# SYSCTL_1.0 register map
Vendor: Texas Instruments
Peripheral module from a debugger description file (folder mspm33c321x).
Registers are 32-bit, read-write, no defined reset value unless marked. A register's access mark holds for its fields unless they carry their own. Offsets are as the file gives them; lines under a group give offsets from that group; [hi:lo] are bit positions; {n}, {i} and the like mark numbered series; 'fields as' and 'values as' point back to an identical list; <NAME> marks a mode.

## SYSCTL (part 1 of 2)
0x800 SYSCTL_MGMT_M33ADC12B4MSPS0_PWREN — IP Enable Register
  [0] ENABLE — IP Enable
    0=Disable; 1=Enable
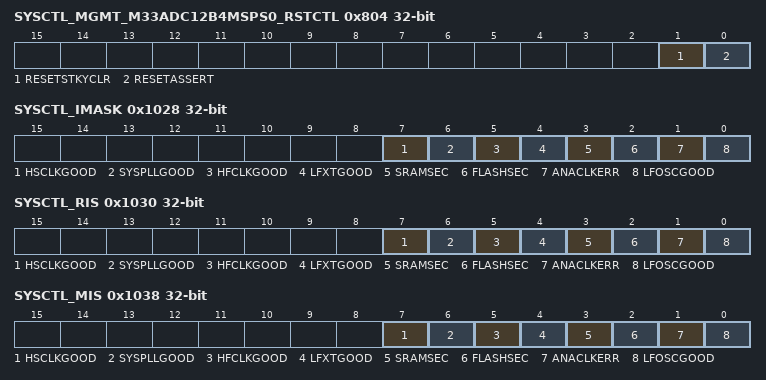
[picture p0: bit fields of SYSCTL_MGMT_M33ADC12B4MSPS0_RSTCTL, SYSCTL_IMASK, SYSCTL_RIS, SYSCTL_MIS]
0x804 SYSCTL_MGMT_M33ADC12B4MSPS0_RSTCTL — Power Control Register - Write Only Register, Always Read as 0
  [1] RESETSTKYCLR — Clear the RESET STICKY Bit
    1=Clear
  [0] RESETASSERT — Assert Reset to IP Domain.
    1=Do
0x814 SYSCTL_MGMT_M33ADC12B4MSPS0_STAT ro — IP State Register - Read Only
  [16] RESETSTKY — IP has been Reset
    0=clear; 1=Set
0x1020 SYSCTL_IIDX ro — SYSCTL interrupt index
  [3:0] STAT — The SYSCTL interrupt index (IIDX) register generates a value corresponding to the highest priority pending interrupt source. This value may be used as an address offset for fast, deterministic handling in the interrupt service routine. A read of the IIDX register will clear the corresponding interrupt status in the RIS and MIS registers.
    0=NO_INTR (No interrupt pending); 1=LFOSCGOOD (LFOSCGOOD interrupt pending); 2=ANACLKERR; 3=FLASHSEC; 4=SRAMSEC; 5=LFXTGOOD; 6=HFCLKGOOD; 7=SYSPLLGOOD; 8=HSCLKGOOD
0x1028 SYSCTL_IMASK — SYSCTL interrupt mask
  [7] HSCLKGOOD
    0=DISABLE; 1=ENABLE
  [6] SYSPLLGOOD
    0=DISABLE; 1=ENABLE
  [5] HFCLKGOOD
    0=DISABLE; 1=ENABLE
  [4] LFXTGOOD
    0=DISABLE; 1=ENABLE
  [3] SRAMSEC — SRAM Single Error Correct
    0=DISABLE; 1=ENABLE
  [2] FLASHSEC — Flash Single Error Correct
    0=DISABLE; 1=ENABLE
  [1] ANACLKERR — Analog Clocking Consistency Error
    0=DISABLE; 1=ENABLE
  [0] LFOSCGOOD — Enable or disable the LFOSCGOOD interrupt. LFOSCGOOD indicates that the LFOSC has started successfully.
    0=DISABLE (Interrupt disabled); 1=ENABLE (Interrupt enabled)
0x1030 SYSCTL_RIS ro — SYSCTL raw interrupt status
  [7] HSCLKGOOD
    0=FALSE; 1=TRUE
  [6] SYSPLLGOOD
    0=FALSE; 1=TRUE
  [5] HFCLKGOOD
    0=FALSE; 1=TRUE
  [4] LFXTGOOD
    0=FALSE; 1=TRUE
  [3] SRAMSEC — SRAM Single Error Correct
    0=FALSE; 1=TRUE
  [2] FLASHSEC — Flash Single Error Correct
    0=FALSE; 1=TRUE
  [1] ANACLKERR — Analog Clocking Consistency Error
    0=FALSE; 1=TRUE
  [0] LFOSCGOOD — Raw status of the LFOSCGOOD interrupt.
    0=FALSE (No interrupt pending); 1=TRUE (Interrupt pending)
0x1038 SYSCTL_MIS ro — SYSCTL masked interrupt status
  [7] HSCLKGOOD
    0=FALSE; 1=TRUE
  [6] SYSPLLGOOD
    0=FALSE; 1=TRUE
  [5] HFCLKGOOD
    0=FALSE; 1=TRUE
  [4] LFXTGOOD
    0=FALSE; 1=TRUE
  [3] SRAMSEC — SRAM Single Error Correct
    0=FALSE; 1=TRUE
  [2] FLASHSEC — Flash Single Error Correct
    0=FALSE; 1=TRUE
  [1] ANACLKERR — Analog Clocking Consistency Error
    0=FALSE; 1=TRUE
  [0] LFOSCGOOD — Masked status of the LFOSCGOOD interrupt.
    0=FALSE (No interrupt pending); 1=TRUE (Interrupt pending)
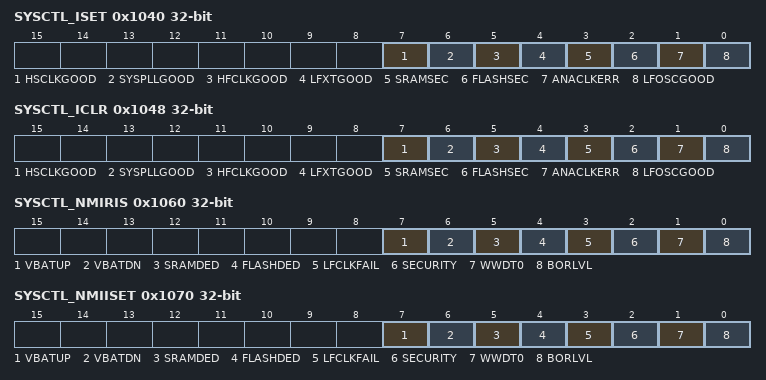
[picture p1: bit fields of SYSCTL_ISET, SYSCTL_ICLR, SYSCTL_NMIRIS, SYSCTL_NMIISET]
0x1040 SYSCTL_ISET — SYSCTL interrupt set
  [7] HSCLKGOOD
    0=NO_EFFECT; 1=SET
  [6] SYSPLLGOOD
    0=NO_EFFECT; 1=SET
  [5] HFCLKGOOD
    0=NO_EFFECT; 1=SET
  [4] LFXTGOOD
    0=NO_EFFECT; 1=SET
  [3] SRAMSEC — SRAM Single Error Correct
    0=NO_EFFECT; 1=SET
  [2] FLASHSEC — Flash Single Error Correct
    0=NO_EFFECT; 1=SET
  [1] ANACLKERR — Analog Clocking Consistency Error
    0=NO_EFFECT; 1=SET
  [0] LFOSCGOOD — Set the LFOSCGOOD interrupt.
    0=NO_EFFECT (Writing 0h hs no effect); 1=SET (Set interrupt)
0x1048 SYSCTL_ICLR — SYSCTL interrupt clear
  [7] HSCLKGOOD
    0=NO_EFFECT; 1=CLR
  [6] SYSPLLGOOD
    0=NO_EFFECT; 1=CLR
  [5] HFCLKGOOD
    0=NO_EFFECT; 1=CLR
  [4] LFXTGOOD
    0=NO_EFFECT; 1=CLR
  [3] SRAMSEC — SRAM Single Error Correct
    0=NO_EFFECT; 1=CLR
  [2] FLASHSEC — Flash Single Error Correct
    0=NO_EFFECT; 1=CLR
  [1] ANACLKERR — Analog Clocking Consistency Error
    0=NO_EFFECT; 1=CLR
  [0] LFOSCGOOD — Clear the LFOSCGOOD interrupt.
    0=NO_EFFECT (Writing 0h has no effect); 1=CLR (Clear interrupt)
0x1050 SYSCTL_NMIIIDX ro — NMI interrupt index
  [3:0] STAT — The NMI interrupt index (NMIIIDX) register generates a value corresponding to the highest priority pending NMI source. This value may be used as an address offset for fast, deterministic handling in the NMI service routine. A read of the NMIIIDX register will clear the corresponding interrupt status in the NMIRIS register.
    0=NO_INTR (No NMI pending); 1=BORLVL (BOR Threshold NMI pending); 2=WWDT0; 3=SECURITY; 4=LFCLKFAIL; 5=FLASHDED; 6=SRAMDED; 7=VBATDN; 8=VBATUP
0x1060 SYSCTL_NMIRIS ro — NMI raw interrupt status
  [7] VBATUP — VBAT Power On
    0=FALSE; 1=TRUE
  [6] VBATDN — VBAT Power Off
    0=FALSE; 1=TRUE
  [5] SRAMDED — SRAM Double Error Detect
    0=FALSE; 1=TRUE
  [4] FLASHDED — Flash Double Error Detect
    0=FALSE; 1=TRUE
  [3] LFCLKFAIL — LFXT-EXLF Monitor Fail
    0=FALSE; 1=TRUE
  [2] SECURITY — Security Fault
    0=FALSE; 1=TRUE
  [1] WWDT0 — Watch Dog 0 Fault
    0=FALSE; 1=TRUE
  [0] BORLVL — Raw status of the BORLVL NMI
    0=FALSE (No interrupt pending); 1=TRUE (Interrupt pending)
0x1070 SYSCTL_NMIISET — NMI interrupt set
  [7] VBATUP — VBAT Power On
    0=NO_EFFECT; 1=SET
  [6] VBATDN — VBAT Power Off
    0=NO_EFFECT; 1=SET
  [5] SRAMDED — SRAM Double Error Detect
    0=NO_EFFECT; 1=SET
  [4] FLASHDED — Flash Double Error Detect
    0=NO_EFFECT; 1=SET
  [3] LFCLKFAIL — LFXT-EXLF Monitor Fail
    0=NO_EFFECT; 1=SET
  [2] SECURITY — Security Fault
    0=NO_EFFECT; 1=SET
  [1] WWDT0 — Watch Dog 0 Fault
    0=NO_EFFECT; 1=SET
  [0] BORLVL — Set the BORLVL NMI
    0=NO_EFFECT (Writing 0h hs no effect); 1=SET (Set interrupt)
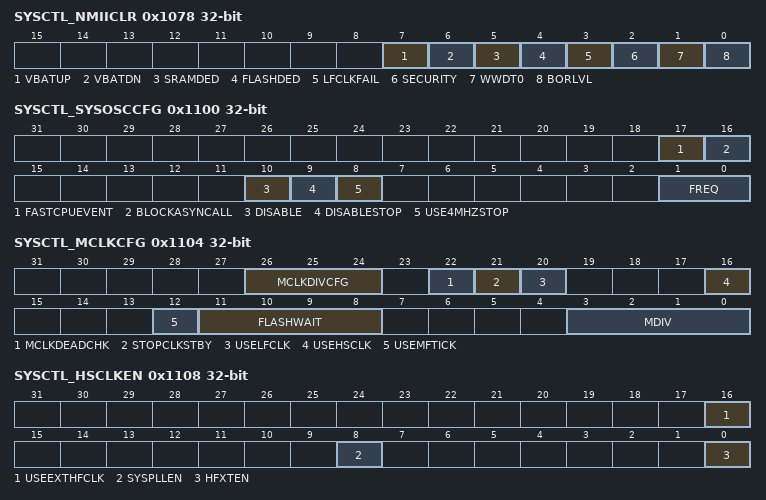
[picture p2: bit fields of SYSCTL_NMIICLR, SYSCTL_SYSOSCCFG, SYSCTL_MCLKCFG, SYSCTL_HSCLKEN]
0x1078 SYSCTL_NMIICLR — NMI interrupt clear
  [7] VBATUP — VBAT Power On
    0=NO_EFFECT; 1=CLR
  [6] VBATDN — VBAT Power Off
    0=NO_EFFECT; 1=CLR
  [5] SRAMDED — SRAM Double Error Detect
    0=NO_EFFECT; 1=CLR
  [4] FLASHDED — Flash Double Error Detect
    0=NO_EFFECT; 1=CLR
  [3] LFCLKFAIL — LFXT-EXLF Monitor Fail
    0=NO_EFFECT; 1=CLR
  [2] SECURITY — Security Fault
    0=NO_EFFECT; 1=CLR
  [1] WWDT0 — Watch Dog 0 Fault
    0=NO_EFFECT; 1=CLR
  [0] BORLVL — Clr the BORLVL NMI
    0=NO_EFFECT (Writing 0h hs no effect); 1=CLR (Clear interrupt)
0x1100 SYSCTL_SYSOSCCFG access per field — SYSOSC configuration
  [17] FASTCPUEVENT rw — if disabled CPU will not wakeup and continue in STANDBY
    0=DISABLE (An interrupt to the CPU will not assert a fast clock request); 1=ENABLE (An interrupt to the CPU will assert a fast clock request)
  [16] BLOCKASYNCALL rw — BLOCKASYNCALL may be used to mask block all asynchronous fast clock requests, preventing hardware from dynamically changing the active clock configuration when operating in a given mode.
    0=DISABLE (Asynchronous fast clock requests are controlled by the requesting peripheral); 1=ENABLE (All asynchronous fast clock requests are blocked)
  [10] DISABLE ro — DISABLE sets the SYSOSC enable/disable policy. SYSOSC may be powered off in RUN, SLEEP, and STOP modes to reduce power consumption. When SYSOSC is disabled, MCLK and ULPCLK are sourced from LFCLK.
    0=DISABLE (Do not disable SYSOSC); 1=ENABLE (Disable SYSOSC immediately and source MCLK and ULPCLK from LFCLK)
  [9] DISABLESTOP ro — DISABLESTOP sets the SYSOSC stop mode enable/disable policy. When operating in STOP mode, the SYSOSC may be automatically disabled. When set, ULPCLK will run from LFCLK in STOP mode and SYSOSC will be disabled to reduce power consumption.
    0=DISABLE (Do not disable SYSOSC in STOP mode); 1=ENABLE (Disable SYSOSC in STOP mode and source ULPCLK from LFCLK)
  [8] USE4MHZSTOP ro — USE4MHZSTOP sets the SYSOSC stop mode frequency policy. When entering STOP mode, the SYSOSC frequency may be automatically switched to 4MHz to reduce SYSOSC power consumption.
    0=DISABLE (Do not gear shift the SYSOSC to 4MHz in STOP mode); 1=ENABLE (Gear shift SYSOSC to 4MHz in STOP mode)
  [1:0] FREQ rw — Target operating frequency for the system oscillator (SYSOSC)
    0=SYSOSCBASE (Base frequency (32MHz)); 1=SYSOSC4M (Low frequency (4MHz))
0x1104 SYSCTL_MCLKCFG access per field — Main clock (MCLK) configuration
  [26:24] MCLKDIVCFG rw — MCLK Divider Configuration bits [1:0] are defined as MCLK4 is Bypass, MCLK2 is Bypass
  [22] MCLKDEADCHK rw — MCLKDEADCHK enables or disables the continuous MCLK dead check monitor. LFCLK must be running before MCLKDEADCHK is enabled.
    0=DISABLE (The MCLK dead check monitor is disabled); 1=ENABLE (The MCLK dead check monitor is enabled)
  [21] STOPCLKSTBY rw — STOPCLKSTBY sets the STANDBY mode policy (STANDBY0 or STANDBY1). When set, ULPCLK and LFCLK are disabled to all peripherals in STANDBY mode, with the exception of TIMG0 and TIMG1 which continue to run. Wake-up is only possible via an asynchronous fast clock request.
    0=DISABLE (ULPCLK/LFCLK runs to all PD0 peripherals in STANDBY mode); 1=ENABLE (ULPCLK/LFCLK is disabled to all peripherals in STANDBY mode except TIMG0 and TIMG1)
  [20] USELFCLK ro — LFCLK is not an MCLK sourcei in PD1, tied 0.
    0=DISABLE (MCLK will not use the low frequency clock (LFCLK)); 1=ENABLE (MCLK will use the low frequency clock (LFCLK))
  [16] USEHSCLK rw — USEHSCLK, together with USELFCLK, sets the MCLK source policy. Set USEHSCLK to use HSCLK (HFCLK or SYSPLL) as the MCLK source in RUN and SLEEP modes.
    0=DISABLE (MCLK will not use the high speed clock (HSCLK)); 1=ENABLE (MCLK will use the high speed clock (HSCLK) in RUN and SLEEP mode)
  [12] USEMFTICK rw — USEMFTICK specifies whether the 4MHz constant-rate clock (MFCLK) to peripherals is enabled or disabled. When enabled, MDIV must be disabled (set to 0h=/1).
    0=DISABLE (The 4MHz rate MFCLK to peripherals is enabled); 1=ENABLE (The 4MHz rate MFCLK to peripherals is enabled.)
  [11:8] FLASHWAIT rw — Not used in design
    0=WAIT0 (No flash wait states are applied); 1=WAIT1 (One flash wait state is applied); 2=WAIT2 (2 flash wait states are applied)
  [3:0] MDIV ro — MDIV tied to 0
0x1108 SYSCTL_HSCLKEN — High-speed clock (HSCLK) source enable/disable
  [16] USEEXTHFCLK — USEEXTHFCLK selects the HFCLK_IN digital clock input to be the source for HFCLK. When disabled, HFXT is the HFCLK source and HFXTEN may be set. Do not set HFXTEN and USEEXTHFCLK simultaneously.
    0=DISABLE (Use HFXT as the HFCLK source); 1=ENABLE (Use the HFCLK_IN digital clock input as the HFCLK source)
  [8] SYSPLLEN — SYSPLLEN enables or disables the system phase-lock loop (SYSPLL).
    0=DISABLE (Disable the SYSPLL); 1=ENABLE (Enable the SYSPLL)
  [0] HFXTEN — HFXTEN enables or disables the high frequency crystal oscillator (HFXT).
    0=DISABLE (Disable the HFXT); 1=ENABLE (Enable the HFXT)
0x110C SYSCTL_HSCLKCFG — High-speed clock (HSCLK) source selection
  [0] HSCLKSEL — HSCLKSEL selects the HSCLK source (SYSPLL or HFCLK).
    0=SYSPLL (HSCLK is sourced from the SYSPLL); 1=HFCLKCLK (HSCLK is sourced from the HFCLK)
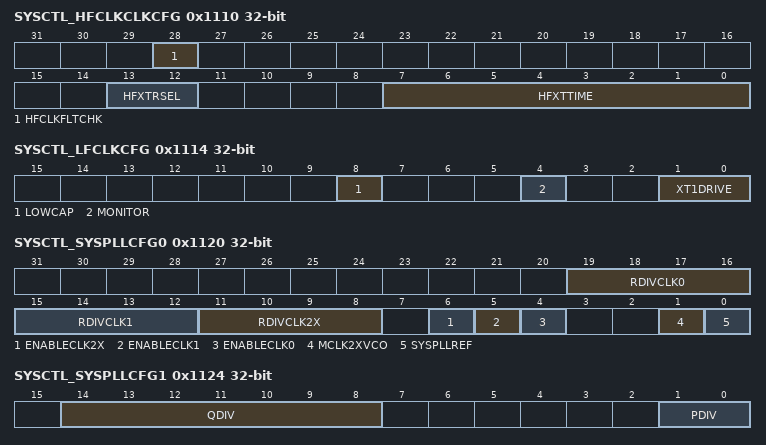
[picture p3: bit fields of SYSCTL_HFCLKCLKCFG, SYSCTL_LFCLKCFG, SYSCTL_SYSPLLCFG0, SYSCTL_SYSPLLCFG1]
0x1110 SYSCTL_HFCLKCLKCFG — High-frequency clock (HFCLK) configuration
  [28] HFCLKFLTCHK — HFCLKFLTCHK enables or disables the HFCLK startup monitor.
    0=DISABLE (HFCLK startup is not checked); 1=ENABLE (HFCLK startup is checked)
  [13:12] HFXTRSEL — HFXT Range Select
    0=RANGE4TO8 (4MHz <= HFXT frequency <= 8MHz); 1=RANGE8TO16 (8MHz < HFXT frequency <= 16MHz); 2=RANGE16TO32 (16MHz < HFXT frequency <= 32MHz); 3=RANGE32TO48 (32MHz < HFXT frequency <= 48MHz)
  [7:0] HFXTTIME — HFXTTIME specifies the HFXT startup time in 64us resolution. If the HFCLK startup monitor is enabled (HFCLKFLTCHK), HFXT will be checked after this time expires.
    0=MINSTARTTIME (Minimum startup time (approximatly zero)); 255=MAXSTARTTIME (Maximum startup time (approximatly 16.32ms))
0x1114 SYSCTL_LFCLKCFG — Low frequency crystal oscillator (LFXT) configuration
  [8] LOWCAP — LOWCAP controls the low-power LFXT mode. When the LFXT load capacitance is less than 3pf, LOWCAP may be set for reduced power consumption.
    0=DISABLE (LFXT low capacitance mode is disabled); 1=ENABLE (LFXT low capacitance mode is enabled)
  [4] MONITOR — MONITOR enables or disables the LFCLK monitor, which continuously checks LFXT or LFCLK_IN for a clock stuck fault.
    0=DISABLE (Clock monitor is disabled); 1=ENABLE (Clock monitor is enabled)
  [1:0] XT1DRIVE — XT1DRIVE selects the low frequency crystal oscillator (LFXT) drive strength.
    0=LOWESTDRV (Lowest drive and current); 1=LOWERDRV (Lower drive and current); 2=HIGHERDRV (Higher drive and current); 3=HIGHESTDRV (Highest drive and current)
0x1120 SYSCTL_SYSPLLCFG0 — SYSPLL reference and output configuration
  [19:16] RDIVCLK0 — RDIVCLK0 sets the final divider for the SYSPLLCLK0 output.
    0=CLK0DIV2 (SYSPLLCLK0 is divided by 2); 1=CLK0DIV4 (SYSPLLCLK0 is divided by 4); 2=CLK0DIV6 (SYSPLLCLK0 is divided by 6); 3=CLK0DIV8 (SYSPLLCLK0 is divided by 8); 4=CLK0DIV10 (SYSPLLCLK0 is divided by 10); 5=CLK0DIV12 (SYSPLLCLK0 is divided by 12); 6=CLK0DIV14 (SYSPLLCLK0 is divided by 14); 7=CLK0DIV16 (SYSPLLCLK0 is divided by 16); 8=CLK0DIV18 (SYSPLLCLK0 is divided by 18); 9=CLK0DIV20 (SYSPLLCLK0 is divided by 20); 10=CLK0DIV22 (SYSPLLCLK0 is divided by 22); 11=CLK0DIV24 (SYSPLLCLK0 is divided by 24); 12=CLK0DIV26 (SYSPLLCLK0 is divided by 26); 13=CLK0DIV28 (SYSPLLCLK0 is divided by 28); 14=CLK0DIV30 (SYSPLLCLK0 is divided by 30); 15=CLK0DIV32 (SYSPLLCLK0 is divided by 32)
  [15:12] RDIVCLK1 — RDIVCLK1 sets the final divider for the SYSPLLCLK1 output.
    0=CLK1DIV2 (SYSPLLCLK1 is divided by 2); 1=CLK1DIV4 (SYSPLLCLK1 is divided by 4); 2=CLK1DIV6 (SYSPLLCLK1 is divided by 6); 3=CLK1DIV8 (SYSPLLCLK1 is divided by 8); 4=CLK1DIV10 (SYSPLLCLK1 is divided by 10); 5=CLK1DIV12 (SYSPLLCLK1 is divided by 12); 6=CLK1DIV14 (SYSPLLCLK1 is divided by 14); 7=CLK1DIV16 (SYSPLLCLK1 is divided by 16); 8=CLK1DIV18 (SYSPLLCLK1 is divided by 18); 9=CLK1DIV20 (SYSPLLCLK1 is divided by 20); 10=CLK1DIV22 (SYSPLLCLK1 is divided by 22); 11=CLK1DIV24 (SYSPLLCLK1 is divided by 24); 12=CLK1DIV26 (SYSPLLCLK1 is divided by 26); 13=CLK1DIV28 (SYSPLLCLK1 is divided by 28); 14=CLK1DIV30 (SYSPLLCLK1 is divided by 30); 15=CLK1DIV32 (SYSPLLCLK1 is divided by 32)
  [11:8] RDIVCLK2X — RDIVCLK2X sets the final divider for the SYSPLLCLK2X output.
    {v}=CLK2XDIV{v+1} (SYSPLLCLK1 is divided by {v+1}) (v=0..15)
  [6] ENABLECLK2X — ENABLECLK2X enables or disables the SYSPLLCLK2X output.
    0=DISABLE (SYSPLLCLK2X is disabled); 1=ENABLE (SYSPLLCLK2X is enabled)
  [5] ENABLECLK1 — ENABLECLK1 enables or disables the SYSPLLCLK1 output.
    0=DISABLE (SYSPLLCLK1 is disabled); 1=ENABLE (SYSPLLCLK1 is enabled)
  [4] ENABLECLK0 — ENABLECLK0 enables or disables the SYSPLLCLK0 output.
    0=DISABLE (SYSPLLCLK0 is disabled); 1=ENABLE (SYSPLLCLK0 is enabled)
  [1] MCLK2XVCO — MCLK2XVCO selects the SYSPLL output which is sent to the HSCLK mux for use by MCLK.
    0=DISABLE (The SYSPLLCLK0 output is sent to the HSCLK mux); 1=ENABLE (The SYSPLLCLK2X output is sent to the HSCLK mux)
  [0] SYSPLLREF — SYSPLLREF selects the system PLL (SYSPLL) reference clock source.
    0=SYSOSC (SYSPLL reference is SYSOSC); 1=HFCLK (SYSPLL reference is HFCLK)
0x1124 SYSCTL_SYSPLLCFG1 — SYSPLL reference and feedback divider
  [14:8] QDIV — QDIV selects the SYSPLL feedback path divider.
    0=INVALID (Divide-by-one is not a valid QDIV option); 1=QDIVMIN (Feedback path is divided by 2); 126=QDIVMAX (Feedback path is divided by 127 (0x7E))
  [1:0] PDIV — PDIV selects the SYSPLL reference clock prescale divider.
    0=REFDIV1 (SYSPLLREF is not divided); 1=REFDIV2 (SYSPLLREF is divided by 2); 2=REFDIV4 (SYSPLLREF is divided by 4); 3=REFDIV8 (SYSPLLREF is divided by 8)
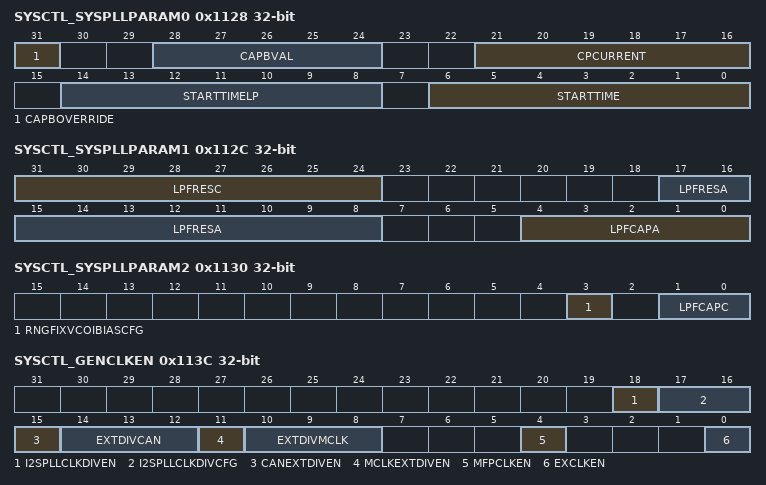
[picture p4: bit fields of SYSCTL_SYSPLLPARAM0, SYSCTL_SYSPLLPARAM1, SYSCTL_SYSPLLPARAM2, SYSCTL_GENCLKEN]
0x1128 SYSCTL_SYSPLLPARAM0 — SYSPLL PARAM0 (load from FACTORY region)
  [31] CAPBOVERRIDE — CAPBOVERRIDE controls the override for Cap B
    0=DISABLE (Cap B override disabled); 1=ENABLE (Cap B override enabled)
  [28:24] CAPBVAL — Override value for Cap B
  [21:16] CPCURRENT — Charge pump current
  [14:8] STARTTIMELP — Startup time from low power mode exit to locked clock, in 1us resolution
  [6:0] STARTTIME — Startup time from enable to locked clock, in 1us resolution
0x112C SYSCTL_SYSPLLPARAM1 — SYSPLL PARAM1 (load from FACTORY region)
  [31:24] LPFRESC — Loop filter Res C
  [17:8] LPFRESA — Loop filter Res A
  [4:0] LPFCAPA — Loop filter Cap A
0x1130 SYSCTL_SYSPLLPARAM2 — SYSPLL PARAM2 (load from FACTORY region)
  [3] RNGFIXVCOIBIASCFG — 0 value for Temperature Compensation R addition
  [1:0] LPFCAPC — Loop filter Cap C
0x1134 SYSCTL_SYSPLLLDOCTL — SYSPLL LDO CTL (load from FACTORY region)
  [15:0] LDOCTLLOWV — LDO Configurability
0x1138 SYSCTL_SYSPLLLDOPROG — SYSPLL LDO VOUT PROG (load from FACTORY region)
  [2:0] LDOVOUTPROGLOWV — HPLL LDO Vout Prog
0x113C SYSCTL_GENCLKEN — General clock enable control
  [18] I2SPLLCLKDIVEN — I2SPLLCLKDIVEN enables or disables the divider function of the PLL Source to I2S.
    0=PASSTHRU (CLock divider is disabled (passthrough, I2SPLLCLKDIV is not applied)); 1=ENABLE (Clock divider is enabled (I2SPLLCLKDIV is applied))
  [17:16] I2SPLLCLKDIVCFG — I2SPLLCLKDIVCFG selects the divider value for the divider for the PLL Source to CAN.
    0=DIV4 (CLK_OUT source is divided by 4); 1=DIV8 (CLK_OUT source is divided by 8); 2=DIV12 (CLK_OUT source is divided by 12); 3=DIV16 (CLK_OUT source is divided by 16)
  [15] CANEXTDIVEN — CANEXTDIVEN enables or disables the divider function of the PLL Source to CAN.
    0=PASSTHRU (CLock divider is disabled (passthrough, EXTDIVCAN is not applied)); 1=ENABLE (Clock divider is enabled (EXTDIVCAN is applied))
  [14:12] EXTDIVCAN — EXTDIVCAN selects the divider value for the divider for the PLL Source to CAN.
    0=DIV2 (CLK_OUT source is divided by 2); 1=DIV4 (CLK_OUT source is divided by 4); 2=DIV6 (CLK_OUT source is divided by 6); 3=DIV8 (CLK_OUT source is divided by 8); 4=DIV10 (CLK_OUT source is divided by 10); 5=DIV12 (CLK_OUT source is divided by 12); 6=DIV14 (CLK_OUT source is divided by 14); 7=DIV16 (CLK_OUT source is divided by 16)
  [11] MCLKEXTDIVEN — MCLKEXTDIVEN enables or disables the divider function of the PLL Source to MCLK.
    0=PASSTHRU (CLock divider is disabled (passthrough, EXTDIVMCLK is not applied)); 1=ENABLE (Clock divider is enabled (EXTDIVMCLK is applied))
  [10:8] EXTDIVMCLK — EXTDIVMCLK selects the divider value for the divider for the PLL Source MCLK.
    values as EXTDIVCAN
  [4] MFPCLKEN — MFPCLKEN tied 0, since DAC is not present
    0=DISABLE (MFPCLK is disabled); 1=ENABLE (MFPCLK is enabled)
  [0] EXCLKEN — EXCLKEN enables the CLK_OUT external clock output block.
    0=DISABLE (CLK_OUT block is disabled); 1=ENABLE (CLK_OUT block is enabled)
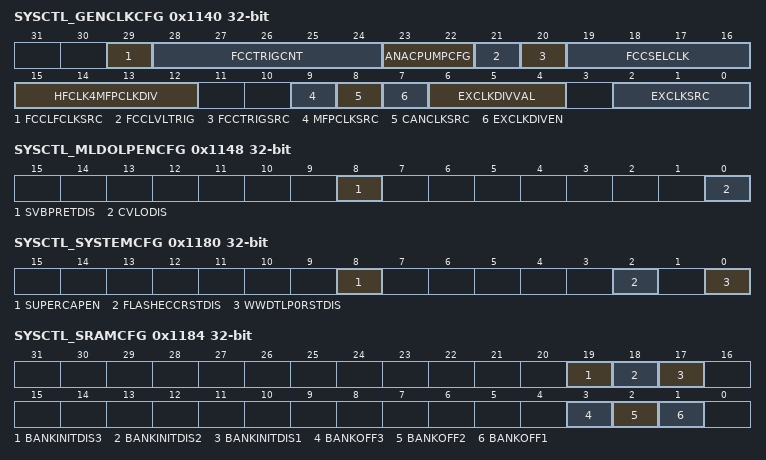
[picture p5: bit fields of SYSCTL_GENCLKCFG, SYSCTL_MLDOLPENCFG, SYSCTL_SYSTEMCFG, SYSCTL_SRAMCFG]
0x1140 SYSCTL_GENCLKCFG — General clock configuration
  [29] FCCLFCLKSRC — FCCLFCLKSRC selects between SYSTEM LFCLK and EXTERNAL SOURCED LFCLK.
  [28:24] FCCTRIGCNT — FCCTRIGCNT specifies the number of trigger clock periods in the trigger window. FCCTRIGCNT=0h (one trigger clock period) up to 1Fh (32 trigger clock periods) may be specified.
  [23:22] ANACPUMPCFG — ANACPUMPCFG selects the analog mux charge pump (VBOOST) enable method.
    0=ONDEMAND (VBOOST is enabled on request from a COMP, GPAMP, or OPA); 1=ONACTIVE (VBOOST is enabled when the device is in RUN or SLEEP mode, or when a COMP/GPAMP/OPA is enabled); 2=ONALWAYS (VBOOST is always enabled)
  [21] FCCLVLTRIG — FCCLVLTRIG selects the frequency clock counter (FCC) trigger mode.
    0=RISE2RISE (Rising edge to rising edge triggered); 1=LEVEL (Level triggered)
  [20] FCCTRIGSRC — FCCTRIGSRC selects the frequency clock counter (FCC) trigger source.
    0=EXTPIN (FCC trigger is the external pin); 1=LFCLK (FCC trigger is the LFCLK)
  [19:16] FCCSELCLK — FCCSELCLK selectes the frequency clock counter (FCC) clock source.
    0=MCLK/4 (FCC clock is MCLK/4); 1=SYSOSC (FCC clock is SYSOSC); 2=HFCLK (FCC clock is HFCLK); 3=EXTCLK (FCC clock is the CLK_OUT selection); 4=SYSPLLCLK0 (FCC clock is SYSPLLCLK0); 5=SYSPLLCLK1 (FCC clock is SYSPLLCLK1); 6=SYSPLLCLK2X (FCC clock is SYSPLLCLK2X); 7=FCCIN (FCC clock is the FCCIN external input)
  [15:12] HFCLK4MFPCLKDIV — HFCLK4MFPCLKDIV selects the divider applied to HFCLK when HFCLK is used as the MFPCLK source. Integer dividers from /1 to /16 may be selected.
    0=DIV1 (HFCLK is not divided before being used for MFPCLK); {v}=DIV{v+1} (HFCLK is divided by {v+1} before being used for MFPCLK) (v=1..15)
  [9] MFPCLKSRC — Not used in design
    0=SYSOSC (MFPCLK is sourced from SYSOSC); 1=HFCLK (MFPCLK is sourced from HFCLK)
  [8] CANCLKSRC — CANCLKSRC selects the CANCLK source.
    0=HFCLK (CANCLK source is HFCLK); 1=SYSPLLOUT1 (CANCLK source is SYSPLLCLK1)
  [7] EXCLKDIVEN — EXCLKDIVEN enables or disables the divider function of the CLK_OUT external clock output block.
    0=PASSTHRU (CLock divider is disabled (passthrough, EXCLKDIVVAL is not applied)); 1=ENABLE (Clock divider is enabled (EXCLKDIVVAL is applied))
  [6:4] EXCLKDIVVAL — EXCLKDIVVAL selects the divider value for the divider in the CLK_OUT external clock output block.
    values as SYSCTL_GENCLKEN.EXTDIVCAN
  [2:0] EXCLKSRC — EXCLKSRC selects the source for the CLK_OUT external clock output block. ULPCLK and MFPCLK require the CLK_OUT divider (EXCLKDIVEN) to be enabled
    0=SYSOSC (CLK_OUT is SYSOSC); 1=ULPCLK (CLK_OUT is ULPCLK (EXCLKDIVEN must be enabled)); 2=LFCLK (CLK_OUT is LFCLK); 3=MFPCLK (CLK_OUT is MFPCLK (EXCLKDIVEN must be enabled)); 4=HFCLK (CLK_OUT is HFCLK); 5=SYSPLLOUT1 (CLK_OUT is SYSPLLCLK1 (SYSPLLCLK1 must be <=48MHz))
0x1144 SYSCTL_PMODECFG — Power mode configuration
  [1:0] DSLEEP — DSLEEP selects the operating mode to enter upon a DEEPSLEEP request from the CPU.
    0=STOP (STOP mode is entered); 1=STANDBY (STANDBY mode is entered); 2=SHUTDOWN (SHUTDOWN mode is entered)
0x1148 SYSCTL_MLDOLPENCFG — LDO Configuration Control
  [8] SVBPRETDIS — Control to disable the disconnect of core LDO from retention for STOP and STANDBY
    0=FALSE (Disconnect the core LDO from retention domain during STOP and STANDBY); 1=TRUE (Do Not Disconnect the core LDO from retention domain during STOP and STANDBY)
  [0] CVLODIS — Control to disable lowering the core voltage for STOP and STANDBY
    0=FALSE (Lower Core Voltage for STOP and STANDBY mode); 1=TRUE (Do Not Lower Core Voltage for STOP and STANDBY mode to provide faster wakeup)
0x1150 SYSCTL_FCC ro — Frequency clock counter (FCC) count
  [21:0] DATA — Frequency clock counter (FCC) count value.
0x1154 SYSCTL_PMULDOSPARECTL — LDO Spare Control
  [3:0] sparectrl — Spare PMU LDO control for M33
0x1158 SYSCTL_SYSCTL_ECO_REG1 access not given — Sysctl ECO Reg 1
0x115C SYSCTL_SYSCTL_ECO_REG2 access not given — Sysctl ECO Reg 2
0x1178 SYSCTL_SRAMBOUNDARY — SRAM Write Boundary
  [19:5] ADDR — Not used, GSC register is used for SRAM boundary configuration
0x117C SYSCTL_SRAMBOUNDARYHIGH — SRAM Write Boundary High
  fields as SYSCTL_SRAMBOUNDARY
0x1180 SYSCTL_SYSTEMCFG — System configuration
  [8] SUPERCAPEN — SUPERCAP specifies whether the battery backup system can be powered by a SUPERCAP
    0=FALSE (SUPERCAP Function is not enabled); 1=TRUE (SUPERCAP Function is not enabled)
  [2] FLASHECCRSTDIS — FLASHECCRSTDIS specifies whether a flash ECC double error detect (DED) will trigger a SYSRST or an NMI.
    0=FALSE (Flash ECC DED will trigger a SYSRST); 1=TRUE (Flash ECC DED will trigger a NMI)
  [0] WWDTLP0RSTDIS — WWDTLP0RSTDIS specifies whether a WWDT Error Event will trigger a BOOTRST or an NMI.
    0=FALSE (WWDTLP0 Error Event will trigger a BOOTRST); 1=TRUE (WWDTLP0 Error Event will trigger an NMI)
0x1184 SYSCTL_SRAMCFG — System SRAM configuration
  [19] BANKINITDIS3 — SRAM BANK3 Initialization
    0=FALSE (SRAM BANK3 will Initialize when transitioning from OFF to ON); 1=TRUE (SRAM BANK3 will NOT Initialize when transitioning from OFF to ON)
  [18] BANKINITDIS2 — SRAM BANK2 Initialization
    0=FALSE (SRAM BANK2 will Initialize when transitioning from OFF to ON); 1=TRUE (SRAM BANK2 will NOT Initialize when transitioning from OFF to ON)
  [17] BANKINITDIS1 — SRAM BANK1 Initialization
    0=FALSE (SRAM BANK1 will Initialize when transitioning from OFF to ON); 1=TRUE (SRAM BANK1 will NOT Initialize when transitioning from OFF to ON)
  [3] BANKOFF3 — Not used
    0=FALSE (SRAM BANK3 power ON for RUN mode); 1=TRUE (SRAM BANK3 power OFF for RUN mode)
  [2] BANKOFF2 — Not used
    0=FALSE (SRAM BANK2 power ON for RUN mode); 1=TRUE (SRAM BANK2 power OFF for RUN mode)
  [1] BANKOFF1 — Not used
    0=FALSE (SRAM BANK1 power ON for RUN mode); 1=TRUE (SRAM BANK1 power OFF for RUN mode)
0x1200 SYSCTL_WRITELOCK — SYSCTL register write lockout
  [0] ACTIVE — ACTIVE controls whether critical SYSCTL registers are write protected or not.
    0=DISABLE (Allow writes to lockable registers); 1=ENABLE (Disallow writes to lockable registers)
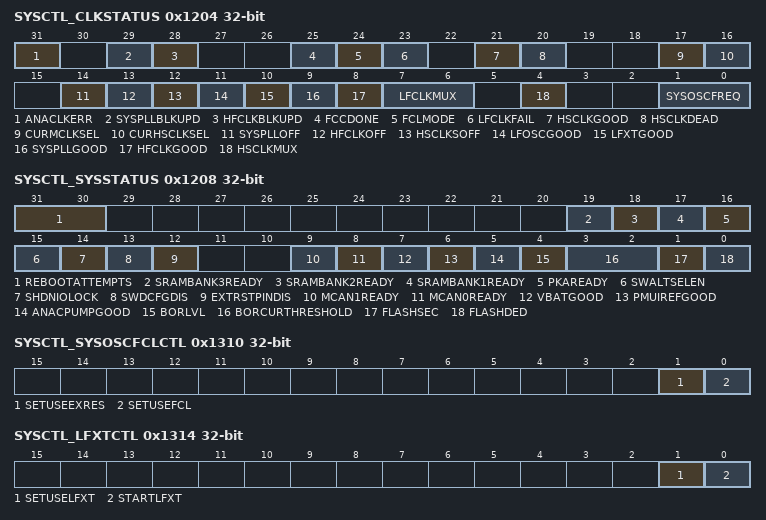
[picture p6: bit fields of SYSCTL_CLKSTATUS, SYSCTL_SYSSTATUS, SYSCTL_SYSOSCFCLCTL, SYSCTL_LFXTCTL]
0x1204 SYSCTL_CLKSTATUS ro — Clock module (CKM) status
  [31] ANACLKERR — ANACLKERR is set when the device clock configuration does not support an enabled analog peripheral mode and the analog peripheral may not be functioning as expected.
    0=FALSE (No analog clock errors detected); 1=TRUE (Analog clock error detected)
  [29] SYSPLLBLKUPD — SYSPLLBLKUPD indicates when writes to SYSPLLCFG0/1 and SYSPLLPARAM0/1 are blocked.
    0=FALSE (writes to SYSPLLCFG0/1 and SYSPLLPARAM0/1 are allowed); 1=TRUE (writes to SYSPLLCFG0/1 and SYSPLLPARAM0/1 are blocked)
  [28] HFCLKBLKUPD — HFCLKBLKUPD indicates when writes to the HFCLKCLKCFG register are blocked.
    0=FALSE (Writes to HFCLKCLKCFG are allowed); 1=TRUE (Writes to HFCLKCLKCFG are blocked)
  [25] FCCDONE — FCCDONE indicates when a frequency clock counter capture is complete.
    0=NOTDONE (FCC capture is not done); 1=DONE (FCC capture is done)
  [24] FCLMODE — FCLMODE indicates if the SYSOSC frequency correction loop (FCL) is enabled.
    0=DISABLED (SYSOSC FCL is disabled); 1=ENABLED (SYSOSC FCL is enabled)
  [23] LFCLKFAIL — LFCLKFAIL indicates when the continous LFCLK monitor detects a LFXT or LFCLK_IN clock stuck failure.
    0=FALSE (No LFCLK fault detected); 1=TRUE (LFCLK stuck fault detected)
  [21] HSCLKGOOD — HSCLKGOOD is set by hardware if the selected clock source for HSCLK started successfully.
    0=FALSE (The HSCLK source did not start correctly); 1=TRUE (The HSCLK source started correctly)
  [20] HSCLKDEAD — HSCLKDEAD is set by hardware if the selected source for HSCLK was started but did not start successfully.
    0=FALSE (The HSCLK source was not started or started correctly); 1=TRUE (The HSCLK source did not start correctly)
  [17] CURMCLKSEL — CURMCLKSEL indicates if MCLK is currently sourced from LFCLK.
    0=NOTLFCLK (MCLK is not sourced from LFCLK); 1=LFCLK (MCLK is sourced from LFCLK)
  [16] CURHSCLKSEL — CURHSCLKSEL indicates the current clock source for HSCLK.
    0=SYSPLL (HSCLK is currently sourced from the SYSPLL); 1=HFCLK (HSCLK is currently sourced from the HFCLK)
  [14] SYSPLLOFF — SYSPLLOFF indicates if the SYSPLL is disabled or was dead at startup. When the SYSPLL is started, SYSPLLOFF is cleared by hardware. Following startup of the SYSPLL, if the SYSPLL startup monitor determines that the SYSPLL was not started correctly, SYSPLLOFF is set.
    0=FALSE (SYSPLL started correctly and is enabled); 1=TRUE (SYSPLL is disabled or was dead startup)
  [13] HFCLKOFF — HFCLKOFF indicates if the HFCLK is disabled or was dead at startup. When the HFCLK is started, HFCLKOFF is cleared by hardware. Following startup of the HFCLK, if the HFCLK startup monitor determines that the HFCLK was not started correctly, HFCLKOFF is set.
    0=FALSE (HFCLK started correctly and is enabled); 1=TRUE (HFCLK is disabled or was dead at startup)
  [12] HSCLKSOFF — HSCLKSOFF is set when the high speed clock sources (SYSPLL, HFCLK) are disabled or dead. It is the logical AND of HFCLKOFF and SYSPLLOFF.
    0=FALSE (SYSPLL, HFCLK, or both were started correctly and remain enabled); 1=TRUE (SYSPLL and HFCLK are both either off or dead)
  [11] LFOSCGOOD — LFOSCGOOD indicates when the LFOSC startup has completed and the LFOSC is ready for use.
    0=FALSE (LFOSC is not ready); 1=TRUE (LFOSC is ready)
  [10] LFXTGOOD — LFXTGOOD indicates if the LFXT started correctly. When the LFXT is started, LFXTGOOD is cleared by hardware. After the startup settling time has expired, the LFXT status is tested. If the LFXT started successfully the LFXTGOOD bit is set, else it is left cleared.
    0=FALSE (LFXT did not start correctly); 1=TRUE (LFXT started correctly)
  [9] SYSPLLGOOD — SYSPLLGOOD indicates if the SYSPLL started correctly. When the SYSPLL is started, SYSPLLGOOD is cleared by hardware. After the startup settling time has expired, the SYSPLL status is tested. If the SYSPLL started successfully the SYSPLLGOOD bit is set, else it is left cleared.
    0=FALSE (SYSPLL did not start correctly); 1=TRUE (SYSPLL started correctly)
  [8] HFCLKGOOD — HFCLKGOOD indicates that the HFCLK started correctly. When the HFXT is started or HFCLK_IN is selected as the HFCLK source, this bit will be set by hardware if a valid HFCLK is detected, and cleared if HFCLK is not operating within the expected range.
    0=FALSE (HFCLK did not start correctly); 1=TRUE (HFCLK started correctly)
  [7:6] LFCLKMUX — LFCLKMUX indicates if LFCLK is sourced from the internal LFOSC, the low frequency crystal (LFXT), or the LFCLK_IN digital clock input.
    0=LFOSC (LFCLK is sourced from the internal LFOSC); 1=LFXT (LFCLK is sourced from the LFXT (crystal)); 2=EXLF (LFCLK is sourced from LFCLK_IN (external digital clock input))
  [4] HSCLKMUX — HSCLKMUX indicates if MCLK is currently sourced from the high-speed clock (HSCLK).
    0=SYSOSC (MCLK is not sourced from HSCLK); 1=HSCLK (MCLK is sourced from HSCLK)
  [1:0] SYSOSCFREQ — SYSOSCFREQ indicates the current SYSOSC operating frequency.
    0=SYSOSC32M (SYSOSC is at base frequency (32MHz)); 1=SYSOSC4M (SYSOSC is at low frequency (4MHz)); 2=SYSOSCUSER (SYSOSC is at the user-trimmed frequency (16 or 24MHz)); 3=SYSOSCTURBO (Reserved)
0x1208 SYSCTL_SYSSTATUS ro — System status information
  [31:30] REBOOTATTEMPTS — REBOOTATTEMPTS indicates the number of boot attempts taken before the user application starts.
  [19] SRAMBANK3READY — SRAM BANK3 READY STATE
    0=FALSE (SRAM BANK3 is NOT READY for access); 1=TRUE (SRAM BANK3 is READY for access)
  [18] SRAMBANK2READY — SRAM BANK2 READY STATE
    0=FALSE (SRAM BANK2 is NOT READY for access); 1=TRUE (SRAM BANK2 is READY for access)
  [17] SRAMBANK1READY — SRAM BANK1 READY STATE
    0=FALSE (SRAM BANK1 is NOT READY for access); 1=TRUE (SRAM BANK1 is READY for access)
  [16] PKAREADY — PKAREADY indicates when the PKA peripheral is ready.
    0=FALSE (PKA is not ready); 1=TRUE (PKA is ready)
  [15] SWALTSELEN — SWALTSELEN indicates when user has enabled the use of alternate SWD/SWCLK pins
    0=FALSE (Alternate SWD/SWCLK pins are disabled); 1=TRUE (Alternate SWD/SWCLK pins are enabled)
  [14] SHDNIOLOCK — SHDNIOLOCK indicates when IO is locked due to SHUTDOWN
    0=FALSE (IO IS NOT Locked due to SHUTDOWN); 1=TRUE (IO IS Locked due to SHUTDOWN)
  [13] SWDCFGDIS — SWDCFGDIS indicates when user has disabled the use of SWD Port
    0=FALSE (SWD Port Enabled); 1=TRUE (SWD Port Disabled)
  [12] EXTRSTPINDIS — EXTRSTPINDIS indicates when user has disabled the use of external reset pin
    0=FALSE (External Reset Pin Enabled); 1=TRUE (External Reset Pin Disabled)
  [9] MCAN1READY — MCAN1READY indicates when the MCAN1 peripheral is ready.
    0=FALSE (MCAN1 is not ready); 1=TRUE (MCAN1 is ready)
  [8] MCAN0READY — MCAN0READY indicates when the MCAN0 peripheral is ready.
    0=FALSE (MCAN0 is not ready); 1=TRUE (MCAN0 is ready)
  [7] VBATGOOD — VBATGOOD is set by hardware when the VBAT Power Domain is valid.
    0=FALSE (VBAT Power Domain is not valid); 1=TRUE (VBAT Power Domain is valid)
  [6] PMUIREFGOOD — PMUIREFGOOD is set by hardware when the PMU current reference is ready.
    0=FALSE (IREF is not ready); 1=TRUE (IREF is ready)
  [5] ANACPUMPGOOD — ANACPUMPGOOD is set by hardware when the VBOOST analog mux charge pump is ready.
    0=FALSE (VBOOST is not ready); 1=TRUE (VBOOST is ready)
  [4] BORLVL — BORLVL indicates if a BOR event occured and the BOR threshold was switched to BOR0 by hardware.
    0=FALSE (No BOR violation occured); 1=TRUE (A BOR violation occured and the BOR threshold was switched to BOR0)
  [3:2] BORCURTHRESHOLD — BORCURTHRESHOLD indicates the active brown-out reset supply monitor configuration.
    0=BORMIN (Default minimum threshold; a BOR0- violation triggers a BOR); 1=BORLEVEL1 (A BOR1- violation generates a BORLVL interrupt); 2=BORLEVEL2 (A BOR2- violation generates a BORLVL interrupt); 3=BORLEVEL3 (A BOR3- violation generates a BORLVL interrupt)
  [1] FLASHSEC — FLASHSEC indicates if a flash ECC single bit error was detected and corrected (SEC).
    0=FALSE (No flash ECC single bit error detected); 1=TRUE (Flash ECC single bit error was detected and corrected)
  [0] FLASHDED — FLASHDED indicates if a flash ECC double bit error was detected (DED).
    0=FALSE (No flash ECC double bit error detected); 1=TRUE (Flash ECC double bit error detected)
0x120C SYSCTL_DEDERRADDR access not given — Memory DED Address
0x1220 SYSCTL_RSTCAUSE ro — Reset cause
  [4:0] ID — ID is a read-to-clear field which indicates the lowest level reset cause since the last read.
    0=NORST (No reset since last read); 1=PORHWFAIL (POR- violation, SHUTDNSTOREx or PMU trim parity fault); 2=POREXNRST (NRST triggered POR (>1s hold)); 3=PORSW (Software triggered POR); 4=BORSUPPLY (BOR0- violation); 5=BORWAKESHUTDN (SHUTDOWN mode exit); 8=BOOTNONPMUPARITY (Non-PMU trim parity fault); 9=BOOTCLKFAIL (Fatal clock failure); 12=BOOTEXNRST (NRST triggered BOOTRST (<1s hold)); 13=BOOTSW (Software triggered BOOTRST); 14=BOOTWWDT0 (WWDT0 violation); 16=SYSBSLEXIT (BSL exit); 17=SYSBSLENTRY (BSL entry); 20=SYSFLASHECC (Flash uncorrectable ECC error); 21=SYSCPULOCK (CPULOCK violation); 26=SYSDBG (Debug triggered SYSRST); 27=SYSSW (Software triggered SYSRST); 28=CPUDBG (Debug triggered CPURST); 29=CPUSW (Software triggered CPURST)
0x1300 SYSCTL_RESETLEVEL — Reset level for application-triggered reset command
  [2:0] LEVEL — LEVEL is used to specify the type of reset to be issued when RESETCMD is set to generate a software triggered reset.
    0=CPU (Issue a SYSRST (CPU plus peripherals only)); 1=BOOT (Issue a BOOTRST (CPU, peripherals, and boot configuration routine)); 2=BOOTLOADERENTRY (Issue a SYSRST and enter the boot strap loader (BSL)); 3=POR (Issue a power-on reset (POR)); 4=BOOTLOADEREXIT (Issue a SYSRST and exit the boot strap loader (BSL))
0x1304 SYSCTL_RESETCMD — Execute an application-triggered reset command
  [0] GO — Execute the reset specified in RESETLEVEL.LEVEL. Must be written together with the KEY.
    1=TRUE (Issue reset)
0x1308 SYSCTL_BORTHRESHOLD — BOR threshold selection
  [1:0] LEVEL — LEVEL specifies the desired BOR threshold and BOR mode.
    values as SYSCTL_SYSSTATUS.BORCURTHRESHOLD
0x130C SYSCTL_BORCLRCMD — Set the BOR threshold
  [0] GO — GO clears any prior BOR violation status indications and attempts to change the active BOR mode to that specified in the LEVEL field of the BORTHRESHOLD register.
    1=TRUE (Issue clear)
0x1310 SYSCTL_SYSOSCFCLCTL — SYSOSC frequency correction loop (FCL) ROSC enable
  [1] SETUSEEXRES — external resistor feature not used for FCL.
    1=TRUE (Enable the SYSOSC external Resistor)
  [0] SETUSEFCL — Set SETUSEFCL to enable the frequency correction loop in SYSOSC. Once enabled, this state is locked until the next BOOTRST.
    1=TRUE (Enable the SYSOSC FCL)
0x1314 SYSCTL_LFXTCTL — LFXT and LFCLK control
  [1] SETUSELFXT — Set SETUSELFXT to switch LFCLK to LFXT. Once set, SETUSELFXT remains set until the next BOOTRST.
    0=FALSE; 1=TRUE (Use LFXT as the LFCLK source)
  [0] STARTLFXT — Set STARTLFXT to start the low frequency crystal oscillator (LFXT). Once set, STARTLFXT remains set until the next BOOTRST.
    0=FALSE (LFXT not started); 1=TRUE (Start LFXT)
0x1318 SYSCTL_EXLFCTL — LFCLK_IN and LFCLK control
  [0] SETUSEEXLF — Set SETUSEEXLF to switch LFCLK to the LFCLK_IN digital clock input. Once set, SETUSEEXLF remains set until the next BOOTRST.
    1=TRUE (Use LFCLK_IN as the LFCLK source)
0x131C SYSCTL_SHDNIOREL — SHUTDOWN IO release control
  [0] RELEASE — Set RELEASE to release the IO after a SHUTDOWN mode exit.
    1=TRUE (Release IO)
0x1320 SYSCTL_EXRSTPIN — Disable the reset function of the NRST pin
  [0] DISABLE — Set DISABLE to disable the reset function of the NRST pin. Once set, this configuration is locked until the next POR.
    0=FALSE (Reset function of NRST pin is enabled); 1=TRUE (Reset function of NRST pin is disabled)
0x1324 SYSCTL_SYSSTATUSCLR — Clear sticky bits of SYSSTATUS
  [0] ALLECC — Set ALLECC to clear all ECC related SYSSTATUS indicators.
    1=CLEAR (Clear ECC error state)
0x1328 SYSCTL_SWDCFG — Disable the SWD function on the SWD pins
  [0] DISABLE — Set DISABLE to disable the SWD function on SWD pins, allowing the SWD pins to be used as GPIO.
    1=TRUE (Disable SWD function on SWD pins)
0x132C SYSCTL_FCCCMD — Frequency clock counter start capture
  [0] GO — Set GO to start a capture with the frequency clock counter (FCC).
    1=TRUE
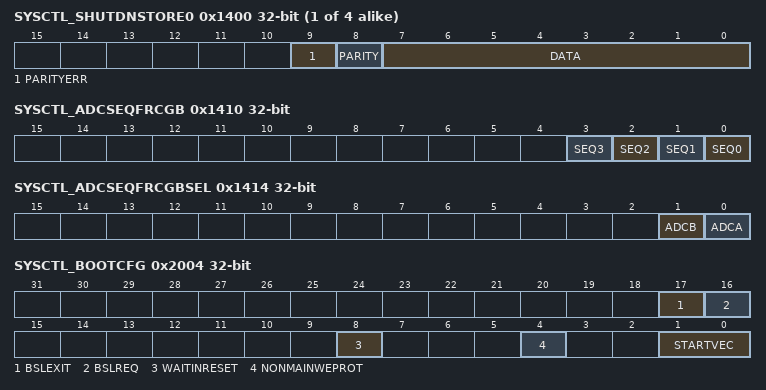
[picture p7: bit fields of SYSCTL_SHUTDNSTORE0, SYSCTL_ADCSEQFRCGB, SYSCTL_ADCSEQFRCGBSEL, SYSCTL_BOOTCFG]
{0x1400+4i} SYSCTL_SHUTDNSTORE{i} access per field (i=0..3) — Shutdown storage memory (byte {i})
  [9] PARITYERR ro — Parity error for SHUTDNSTORE{i}
  [8] PARITY rw — Parity for SHUTDNSTORE{i}
  [7:0] DATA rw — Shutdown storage byte {i}
0x1410 SYSCTL_ADCSEQFRCGB — ADC Global Sequence Force
  [n] SEQ{n} (n=0..3) — Generate synchronous SW trigger for SEQ{n}
0x1414 SYSCTL_ADCSEQFRCGBSEL — ADC Global Sequence Force Select
  [1] ADCB — Generate synchronous SW trigger for ADCB
  [0] ADCA — Generate synchronous SW trigger for ADCA
0x1418 SYSCTL_M33SPARESOCLOCK1 access not given — M33C1 Spare SOC LOCK Reg 1
0x141C SYSCTL_M33SPARESOCLOCK2 access not given — M33C1 Spare SOC LOCK Reg 2
0x1420 SYSCTL_SYSCTL_READ_REG access not given — Sysctl read only Reg
0x2000 SYSCTL_LIFECYCLE — Device Lifecycle
  [7:0] VALUE — Device Lifecycle set by BOOTCODE READY=0x96(150), ATTEST=0x55(85), PREPROBE=0x69(105), Others=BAD/DCOM
    85=ATTEST (Device in TI Test Mode); 105=PREPROBE (Device in Pre Probe State); 150=READY (Device in Product Mode)
0x2004 SYSCTL_BOOTCFG — Configuration of CPURESET Vector
  [17] BSLEXIT — 0: Full Bringup 1: TRIM already loaded, requesting BSL Exit
  [16] BSLREQ — 0: Full Bringup 1: TRIM already loaded, requesting BSL Entry
  [8] WAITINRESET — 0: Normal operation 1: CPU held in reset for debugger to control release
  [4] NONMAINWEPROT — 0: NonMain Flash area can be modified 1: Program-Erase will be ignored
  [1:0] STARTVEC — Reset Vector target location at next reset
    0=BOOTCODE (Reset to BOOTCODE); 1=BOOTLOADER (Reset to BOOTLOADER); 2=APPFLASH (Reset to FLASH 0x0); 3=APPSRAM (Reset to SRAM 0x0)
0x2008 SYSCTL_BOOTDONE — BOOTCODE PASS
  [0] PASS — BOOTCODE writes 1 for PASS, left unwritten a timeout will occur if not blocked
    1=TRUE (BOOTCODE PASS)
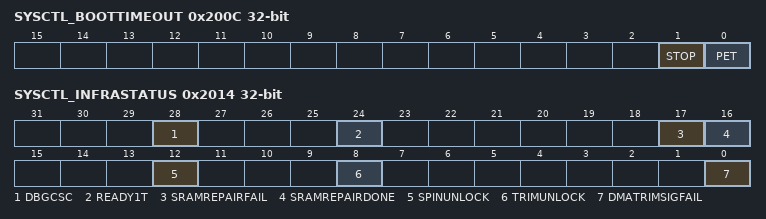
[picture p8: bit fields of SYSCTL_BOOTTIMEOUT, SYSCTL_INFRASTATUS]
0x200C SYSCTL_BOOTTIMEOUT — BOOT TIMEOUT Control
  [1] STOP — BOOTCODE writes 1 for STOPPING BOOT TIMEOUT Counter
    1=TRUE (STOP Bootcode Timeout Counter)
  [0] PET — BOOTCODE writes 1 for reloading BOOT TIMEOUT Counter
    1=TRUE (Restart Bootcode Timeout Counter)
0x2010 SYSCTL_BCTRIMUNLOCK access not given — BootCode TRIM Unlock
0x2014 SYSCTL_INFRASTATUS ro — Infrastructure Status
  [28] DBGCSC — Debug Of Customer Startup Code is ALLOWED
  [24] READY1T — Flash 1T Read mode is available
  [17] SRAMREPAIRFAIL — SRAM repair has failed
  [16] SRAMREPAIRDONE — SRAM repair is completed or not supported on this SOC
  [12] SPINUNLOCK — SPIN MMRs are UNLOCKED
  [8] TRIMUNLOCK — TRIM MMRs are UNLOCKED
  [0] DMATRIMSIGFAIL — DMA TRIM signiture fail
